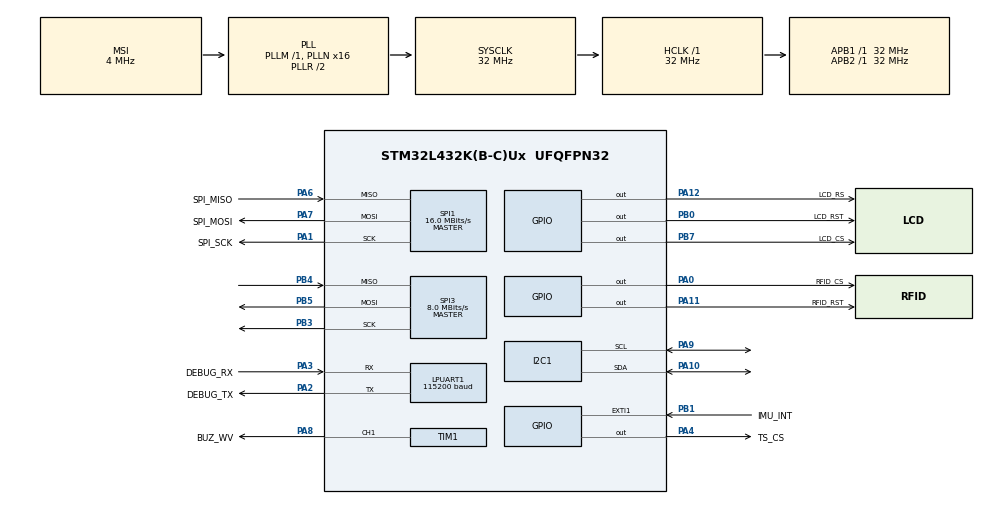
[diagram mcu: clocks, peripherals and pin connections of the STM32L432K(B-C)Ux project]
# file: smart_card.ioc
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Dma.Request0=SPI1_TX
Dma.Request1=SPI1_RX
Dma.SPI1_RX.1.Direction=DMA_PERIPH_TO_MEMORY
Dma.SPI1_RX.1.Instance=DMA1_Channel2
Dma.SPI1_RX.1.MemDataAlignment=DMA_MDATAALIGN_BYTE
Dma.SPI1_RX.1.MemInc=DMA_MINC_ENABLE
Dma.SPI1_RX.1.Mode=DMA_NORMAL
Dma.SPI1_RX.1.PeriphDataAlignment=DMA_PDATAALIGN_BYTE
Dma.SPI1_RX.1.PeriphInc=DMA_PINC_DISABLE
Dma.SPI1_RX.1.Priority=DMA_PRIORITY_LOW
Dma.SPI1_TX.0.Direction=DMA_MEMORY_TO_PERIPH
Dma.SPI1_TX.0.Instance=DMA1_Channel3
Dma.SPI1_TX.0.MemDataAlignment=DMA_MDATAALIGN_BYTE
Dma.SPI1_TX.0.MemInc=DMA_MINC_ENABLE
Dma.SPI1_TX.0.Mode=DMA_NORMAL
Dma.SPI1_TX.0.PeriphDataAlignment=DMA_PDATAALIGN_BYTE
Dma.SPI1_TX.0.PeriphInc=DMA_PINC_DISABLE
Dma.SPI1_TX.0.Priority=DMA_PRIORITY_LOW
I2C1.Timing=0x00B07CB4
LPUART1.BaudRate=115200
LPUART1.WordLength=UART_WORDLENGTH_8B
Mcu.Family=STM32L4
Mcu.Name=STM32L432K(B-C)Ux
Mcu.Package=UFQFPN32
NVIC.DMA1_Channel2_IRQn=true\:0\:0\:false\:false\:true\:false\:true\:true
NVIC.DMA1_Channel3_IRQn=true\:0\:0\:false\:false\:true\:false\:true\:true
NVIC.EXTI1_IRQn=true\:0\:0\:false\:false\:true\:true\:true\:true
NVIC.PriorityGroup=NVIC_PRIORITYGROUP_4
NVIC.TIM7_IRQn=true\:0\:0\:false\:false\:true\:true\:true\:true
PA0.GPIO_Label=RFID_CS
PA0.Signal=GPIO_Output
PA1.GPIO_Label=SPI_SCK
PA1.Mode=Full_Duplex_Master
PA1.Signal=SPI1_SCK
PA10.Mode=I2C
PA10.Signal=I2C1_SDA
PA11.GPIO_Label=RFID_RST
PA11.Signal=GPIO_Output
PA12.GPIO_Label=LCD_RS
PA12.GPIO_Speed=GPIO_SPEED_FREQ_VERY_HIGH
PA12.Signal=GPIO_Output
PA2.GPIO_Label=DEBUG_TX
PA2.Mode=Asynchronous
PA2.Signal=LPUART1_TX
PA3.GPIO_Label=DEBUG_RX
PA3.Mode=Asynchronous
PA3.Signal=LPUART1_RX
PA4.GPIO_Label=TS_CS
PA4.GPIO_Speed=GPIO_SPEED_FREQ_VERY_HIGH
PA4.PinState=GPIO_PIN_SET
PA4.Signal=GPIO_Output
PA6.GPIO_Label=SPI_MISO
PA6.Mode=Full_Duplex_Master
PA6.Signal=SPI1_MISO
PA7.GPIO_Label=SPI_MOSI
PA7.Mode=Full_Duplex_Master
PA7.Signal=SPI1_MOSI
PA8.GPIO_Label=BUZ_WV
PA8.Signal=S_TIM1_CH1
PA9.Mode=I2C
PA9.Signal=I2C1_SCL
PB0.GPIO_Label=LCD_RST
PB0.PinState=GPIO_PIN_SET
PB0.Signal=GPIO_Output
PB1.GPIO_Label=IMU_INT
PB1.GPIO_ModeDefaultEXTI=GPIO_MODE_IT_RISING_FALLING
PB1.Signal=GPXTI1
PB3\ (JTDO-TRACESWO).Mode=Full_Duplex_Master
PB3\ (JTDO-TRACESWO).Signal=SPI3_SCK
PB4\ (NJTRST).Mode=Full_Duplex_Master
PB4\ (NJTRST).Signal=SPI3_MISO
PB5.Mode=Full_Duplex_Master
PB5.Signal=SPI3_MOSI
PB7.GPIO_Label=LCD_CS
PB7.GPIO_Speed=GPIO_SPEED_FREQ_VERY_HIGH
PB7.PinState=GPIO_PIN_SET
PB7.Signal=GPIO_Output
ProjectManager.HeapSize=0x200
ProjectManager.StackSize=0x400
ProjectManager.TargetToolchain=STM32CubeIDE
RCC.AHBFreq_Value=32000000
RCC.APB1Freq_Value=32000000
RCC.APB1TimFreq_Value=32000000
RCC.APB2Freq_Value=32000000
RCC.APB2TimFreq_Value=32000000
RCC.CortexFreq_Value=32000000
RCC.HCLKFreq_Value=32000000
RCC.HSE_VALUE=8000000
RCC.HSI16_VALUE=16000000
RCC.HSI48_VALUE=48000000
RCC.HSI_VALUE=16000000
RCC.LSE_VALUE=32768
RCC.MSI_VALUE=4000000
RCC.PLLMUL=RCC_PLLMUL_4
RCC.PLLN=16
RCC.SYSCLKFreq_VALUE=32000000
RCC.SYSCLKSource=RCC_SYSCLKSOURCE_PLLCLK
RCC.VCOOutputFreq_Value=64000000
SH.S_TIM1_CH1.0=TIM1_CH1,PWM Generation1 CH1
SPI1.BaudRatePrescaler=SPI_BAUDRATEPRESCALER_2
SPI1.CalculateBaudRate=16.0 MBits/s
SPI1.DataSize=SPI_DATASIZE_8BIT
SPI1.Direction=SPI_DIRECTION_2LINES
SPI1.Mode=SPI_MODE_MASTER
SPI1.VirtualType=VM_MASTER
SPI3.BaudRatePrescaler=SPI_BAUDRATEPRESCALER_4
SPI3.CalculateBaudRate=8.0 MBits/s
SPI3.DataSize=SPI_DATASIZE_8BIT
SPI3.Direction=SPI_DIRECTION_2LINES
SPI3.Mode=SPI_MODE_MASTER
SPI3.VirtualType=VM_MASTER
TIM1.Channel-PWM\ Generation1\ CH1=TIM_CHANNEL_1
TIM1.Period=1000
TIM1.Pulse-PWM\ Generation1\ CH1=500
TIM7.Period=999
TIM7.Prescaler=31
VP_TIM1_VS_ClockSourceINT.Mode=Internal
VP_TIM7_VS_ClockSourceINT.Mode=Enable_Timer
board=NUCLEO-L432KC

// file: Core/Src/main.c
/* USER CODE BEGIN Header */
/**
 ******************************************************************************
 * @file           : main.c
 * @brief          : Main program body
 ******************************************************************************
 * @attention
 *
 * Copyright (c) 2024 STMicroelectronics.
 * All rights reserved.
 *
 * This software is licensed under terms that can be found in the LICENSE file
 * in the root directory of this software component.
 * If no LICENSE file comes with this software, it is provided AS-IS.
 *
 ******************************************************************************
 */
/* USER CODE END Header */
#include "main.h"

/* USER CODE BEGIN PD */
// TODO comment this out to test just card operations
// #define SCREEN
/* USER CODE END PD */

I2C_HandleTypeDef hi2c1;

UART_HandleTypeDef hlpuart1;

SPI_HandleTypeDef hspi1;
SPI_HandleTypeDef hspi3;
DMA_HandleTypeDef hdma_spi1_tx;
DMA_HandleTypeDef hdma_spi1_rx;

TIM_HandleTypeDef htim1;
TIM_HandleTypeDef htim7;

void SystemClock_Config(void);
static void MX_GPIO_Init(void);
static void MX_DMA_Init(void);
static void MX_LPUART1_UART_Init(void);
static void MX_SPI1_Init(void);
static void MX_SPI3_Init(void);
static void MX_I2C1_Init(void);
static void MX_TIM1_Init(void);
static void MX_TIM7_Init(void);
/* USER CODE BEGIN PFP */
void init();
void loop();
// struct contact_t get_data(uint8_t req);

/* USER CODE END PFP */

int main(void)
{

  /* MCU Configuration--------------------------------------------------------*/

  /* Reset of all peripherals, Initializes the Flash interface and the Systick. */
  HAL_Init();

  /* Configure the system clock */
  SystemClock_Config();

  /* Initialize all configured peripherals */
  MX_GPIO_Init();
  MX_DMA_Init();
  MX_LPUART1_UART_Init();
  MX_SPI1_Init();
  MX_SPI3_Init();
  MX_I2C1_Init();
  MX_TIM1_Init();
  MX_TIM7_Init();
  /* USER CODE BEGIN 2 */
    // HAL_Delay(5000);
    init();
    loop();
  /* USER CODE END 2 */

  /* Infinite loop */
  /* USER CODE BEGIN WHILE */
    while (1) {
        HAL_Delay(1000);
    /* USER CODE END WHILE */

    }
}

void SystemClock_Config(void)
{
  RCC_OscInitTypeDef RCC_OscInitStruct = {0};
  RCC_ClkInitTypeDef RCC_ClkInitStruct = {0};

  /** Configure the main internal regulator output voltage
  */
  if (HAL_PWREx_ControlVoltageScaling(PWR_REGULATOR_VOLTAGE_SCALE1) != HAL_OK)
  {
    Error_Handler();
  }

  /** Initializes the RCC Oscillators according to the specified parameters
  * in the RCC_OscInitTypeDef structure.
  */
  RCC_OscInitStruct.OscillatorType = RCC_OSCILLATORTYPE_MSI;
  RCC_OscInitStruct.MSIState = RCC_MSI_ON;
  RCC_OscInitStruct.MSICalibrationValue = 0;
  RCC_OscInitStruct.MSIClockRange = RCC_MSIRANGE_6;
  RCC_OscInitStruct.PLL.PLLState = RCC_PLL_ON;
  RCC_OscInitStruct.PLL.PLLSource = RCC_PLLSOURCE_MSI;
  RCC_OscInitStruct.PLL.PLLM = 1;
  RCC_OscInitStruct.PLL.PLLN = 16;
  RCC_OscInitStruct.PLL.PLLP = RCC_PLLP_DIV7;
  RCC_OscInitStruct.PLL.PLLQ = RCC_PLLQ_DIV2;
  RCC_OscInitStruct.PLL.PLLR = RCC_PLLR_DIV2;
  if (HAL_RCC_OscConfig(&RCC_OscInitStruct) != HAL_OK)
  {
    Error_Handler();
  }

  /** Initializes the CPU, AHB and APB buses clocks
  */
  RCC_ClkInitStruct.ClockType = RCC_CLOCKTYPE_HCLK|RCC_CLOCKTYPE_SYSCLK
                              |RCC_CLOCKTYPE_PCLK1|RCC_CLOCKTYPE_PCLK2;
  RCC_ClkInitStruct.SYSCLKSource = RCC_SYSCLKSOURCE_PLLCLK;
  RCC_ClkInitStruct.AHBCLKDivider = RCC_SYSCLK_DIV1;
  RCC_ClkInitStruct.APB1CLKDivider = RCC_HCLK_DIV1;
  RCC_ClkInitStruct.APB2CLKDivider = RCC_HCLK_DIV1;

  if (HAL_RCC_ClockConfig(&RCC_ClkInitStruct, FLASH_LATENCY_1) != HAL_OK)
  {
    Error_Handler();
  }
}

static void MX_I2C1_Init(void)
{

  hi2c1.Instance = I2C1;
  hi2c1.Init.Timing = 0x00B07CB4;
  hi2c1.Init.OwnAddress1 = 0;
  hi2c1.Init.AddressingMode = I2C_ADDRESSINGMODE_7BIT;
  hi2c1.Init.DualAddressMode = I2C_DUALADDRESS_DISABLE;
  hi2c1.Init.OwnAddress2 = 0;
  hi2c1.Init.OwnAddress2Masks = I2C_OA2_NOMASK;
  hi2c1.Init.GeneralCallMode = I2C_GENERALCALL_DISABLE;
  hi2c1.Init.NoStretchMode = I2C_NOSTRETCH_DISABLE;
  if (HAL_I2C_Init(&hi2c1) != HAL_OK)
  {
    Error_Handler();
  }

  /** Configure Analogue filter
  */
  if (HAL_I2CEx_ConfigAnalogFilter(&hi2c1, I2C_ANALOGFILTER_ENABLE) != HAL_OK)
  {
    Error_Handler();
  }

  /** Configure Digital filter
  */
  if (HAL_I2CEx_ConfigDigitalFilter(&hi2c1, 0) != HAL_OK)
  {
    Error_Handler();
  }

}

static void MX_LPUART1_UART_Init(void)
{

  hlpuart1.Instance = LPUART1;
  hlpuart1.Init.BaudRate = 115200;
  hlpuart1.Init.WordLength = UART_WORDLENGTH_8B;
  hlpuart1.Init.StopBits = UART_STOPBITS_1;
  hlpuart1.Init.Parity = UART_PARITY_NONE;
  hlpuart1.Init.Mode = UART_MODE_TX_RX;
  hlpuart1.Init.HwFlowCtl = UART_HWCONTROL_NONE;
  hlpuart1.Init.OneBitSampling = UART_ONE_BIT_SAMPLE_DISABLE;
  hlpuart1.AdvancedInit.AdvFeatureInit = UART_ADVFEATURE_NO_INIT;
  if (HAL_UART_Init(&hlpuart1) != HAL_OK)
  {
    Error_Handler();
  }

}

static void MX_SPI1_Init(void)
{

  /* SPI1 parameter configuration*/
  hspi1.Instance = SPI1;
  hspi1.Init.Mode = SPI_MODE_MASTER;
  hspi1.Init.Direction = SPI_DIRECTION_2LINES;
  hspi1.Init.DataSize = SPI_DATASIZE_8BIT;
  hspi1.Init.CLKPolarity = SPI_POLARITY_LOW;
  hspi1.Init.CLKPhase = SPI_PHASE_1EDGE;
  hspi1.Init.NSS = SPI_NSS_SOFT;
  hspi1.Init.BaudRatePrescaler = SPI_BAUDRATEPRESCALER_2;
  hspi1.Init.FirstBit = SPI_FIRSTBIT_MSB;
  hspi1.Init.TIMode = SPI_TIMODE_DISABLE;
  hspi1.Init.CRCCalculation = SPI_CRCCALCULATION_DISABLE;
  hspi1.Init.CRCPolynomial = 7;
  hspi1.Init.CRCLength = SPI_CRC_LENGTH_DATASIZE;
  hspi1.Init.NSSPMode = SPI_NSS_PULSE_ENABLE;
  if (HAL_SPI_Init(&hspi1) != HAL_OK)
  {
    Error_Handler();
  }

}

static void MX_SPI3_Init(void)
{

  /* SPI3 parameter configuration*/
  hspi3.Instance = SPI3;
  hspi3.Init.Mode = SPI_MODE_MASTER;
  hspi3.Init.Direction = SPI_DIRECTION_2LINES;
  hspi3.Init.DataSize = SPI_DATASIZE_8BIT;
  hspi3.Init.CLKPolarity = SPI_POLARITY_LOW;
  hspi3.Init.CLKPhase = SPI_PHASE_1EDGE;
  hspi3.Init.NSS = SPI_NSS_SOFT;
  hspi3.Init.BaudRatePrescaler = SPI_BAUDRATEPRESCALER_4;
  hspi3.Init.FirstBit = SPI_FIRSTBIT_MSB;
  hspi3.Init.TIMode = SPI_TIMODE_DISABLE;
  hspi3.Init.CRCCalculation = SPI_CRCCALCULATION_DISABLE;
  hspi3.Init.CRCPolynomial = 7;
  hspi3.Init.CRCLength = SPI_CRC_LENGTH_DATASIZE;
  hspi3.Init.NSSPMode = SPI_NSS_PULSE_ENABLE;
  if (HAL_SPI_Init(&hspi3) != HAL_OK)
  {
    Error_Handler();
  }

}

static void MX_TIM1_Init(void)
{

  TIM_ClockConfigTypeDef sClockSourceConfig = {0};
  TIM_MasterConfigTypeDef sMasterConfig = {0};
  TIM_OC_InitTypeDef sConfigOC = {0};
  TIM_BreakDeadTimeConfigTypeDef sBreakDeadTimeConfig = {0};

  htim1.Instance = TIM1;
  htim1.Init.Prescaler = 0;
  htim1.Init.CounterMode = TIM_COUNTERMODE_UP;
  htim1.Init.Period = 1000;
  htim1.Init.ClockDivision = TIM_CLOCKDIVISION_DIV1;
  htim1.Init.RepetitionCounter = 0;
  htim1.Init.AutoReloadPreload = TIM_AUTORELOAD_PRELOAD_DISABLE;
  if (HAL_TIM_Base_Init(&htim1) != HAL_OK)
  {
    Error_Handler();
  }
  sClockSourceConfig.ClockSource = TIM_CLOCKSOURCE_INTERNAL;
  if (HAL_TIM_ConfigClockSource(&htim1, &sClockSourceConfig) != HAL_OK)
  {
    Error_Handler();
  }
  if (HAL_TIM_PWM_Init(&htim1) != HAL_OK)
  {
    Error_Handler();
  }
  sMasterConfig.MasterOutputTrigger = TIM_TRGO_RESET;
  sMasterConfig.MasterOutputTrigger2 = TIM_TRGO2_RESET;
  sMasterConfig.MasterSlaveMode = TIM_MASTERSLAVEMODE_DISABLE;
  if (HAL_TIMEx_MasterConfigSynchronization(&htim1, &sMasterConfig) != HAL_OK)
  {
    Error_Handler();
  }
  sConfigOC.OCMode = TIM_OCMODE_PWM1;
  sConfigOC.Pulse = 500;
  sConfigOC.OCPolarity = TIM_OCPOLARITY_HIGH;
  sConfigOC.OCNPolarity = TIM_OCNPOLARITY_HIGH;
  sConfigOC.OCFastMode = TIM_OCFAST_DISABLE;
  sConfigOC.OCIdleState = TIM_OCIDLESTATE_RESET;
  sConfigOC.OCNIdleState = TIM_OCNIDLESTATE_RESET;
  if (HAL_TIM_PWM_ConfigChannel(&htim1, &sConfigOC, TIM_CHANNEL_1) != HAL_OK)
  {
    Error_Handler();
  }
  sBreakDeadTimeConfig.OffStateRunMode = TIM_OSSR_DISABLE;
  sBreakDeadTimeConfig.OffStateIDLEMode = TIM_OSSI_DISABLE;
  sBreakDeadTimeConfig.LockLevel = TIM_LOCKLEVEL_OFF;
  sBreakDeadTimeConfig.DeadTime = 0;
  sBreakDeadTimeConfig.BreakState = TIM_BREAK_DISABLE;
  sBreakDeadTimeConfig.BreakPolarity = TIM_BREAKPOLARITY_HIGH;
  sBreakDeadTimeConfig.BreakFilter = 0;
  sBreakDeadTimeConfig.Break2State = TIM_BREAK2_DISABLE;
  sBreakDeadTimeConfig.Break2Polarity = TIM_BREAK2POLARITY_HIGH;
  sBreakDeadTimeConfig.Break2Filter = 0;
  sBreakDeadTimeConfig.AutomaticOutput = TIM_AUTOMATICOUTPUT_DISABLE;
  if (HAL_TIMEx_ConfigBreakDeadTime(&htim1, &sBreakDeadTimeConfig) != HAL_OK)
  {
    Error_Handler();
  }
  HAL_TIM_MspPostInit(&htim1);

}

static void MX_TIM7_Init(void)
{

  TIM_MasterConfigTypeDef sMasterConfig = {0};

  htim7.Instance = TIM7;
  htim7.Init.Prescaler = 31;
  htim7.Init.CounterMode = TIM_COUNTERMODE_UP;
  htim7.Init.Period = 999;
  htim7.Init.AutoReloadPreload = TIM_AUTORELOAD_PRELOAD_DISABLE;
  if (HAL_TIM_Base_Init(&htim7) != HAL_OK)
  {
    Error_Handler();
  }
  sMasterConfig.MasterOutputTrigger = TIM_TRGO_RESET;
  sMasterConfig.MasterSlaveMode = TIM_MASTERSLAVEMODE_DISABLE;
  if (HAL_TIMEx_MasterConfigSynchronization(&htim7, &sMasterConfig) != HAL_OK)
  {
    Error_Handler();
  }

}

static void MX_DMA_Init(void)
{

  /* DMA controller clock enable */
  __HAL_RCC_DMA1_CLK_ENABLE();

  /* DMA interrupt init */
  /* DMA1_Channel2_IRQn interrupt configuration */
  HAL_NVIC_SetPriority(DMA1_Channel2_IRQn, 0, 0);
  HAL_NVIC_EnableIRQ(DMA1_Channel2_IRQn);
  /* DMA1_Channel3_IRQn interrupt configuration */
  HAL_NVIC_SetPriority(DMA1_Channel3_IRQn, 0, 0);
  HAL_NVIC_EnableIRQ(DMA1_Channel3_IRQn);

}

static void MX_GPIO_Init(void)
{
  GPIO_InitTypeDef GPIO_InitStruct = {0};

  /* GPIO Ports Clock Enable */
  __HAL_RCC_GPIOA_CLK_ENABLE();
  __HAL_RCC_GPIOB_CLK_ENABLE();

  /*Configure GPIO pin Output Level */
  HAL_GPIO_WritePin(GPIOA, RFID_CS_Pin|RFID_RST_Pin|LCD_RS_Pin, GPIO_PIN_RESET);

  /*Configure GPIO pin Output Level */
  HAL_GPIO_WritePin(TS_CS_GPIO_Port, TS_CS_Pin, GPIO_PIN_SET);

  /*Configure GPIO pin Output Level */
  HAL_GPIO_WritePin(GPIOB, LCD_RST_Pin|LCD_CS_Pin, GPIO_PIN_SET);

  /*Configure GPIO pins : RFID_CS_Pin RFID_RST_Pin */
  GPIO_InitStruct.Pin = RFID_CS_Pin|RFID_RST_Pin;
  GPIO_InitStruct.Mode = GPIO_MODE_OUTPUT_PP;
  GPIO_InitStruct.Pull = GPIO_NOPULL;
  GPIO_InitStruct.Speed = GPIO_SPEED_FREQ_LOW;
  HAL_GPIO_Init(GPIOA, &GPIO_InitStruct);

  /*Configure GPIO pins : TS_CS_Pin LCD_RS_Pin */
  GPIO_InitStruct.Pin = TS_CS_Pin|LCD_RS_Pin;
  GPIO_InitStruct.Mode = GPIO_MODE_OUTPUT_PP;
  GPIO_InitStruct.Pull = GPIO_NOPULL;
  GPIO_InitStruct.Speed = GPIO_SPEED_FREQ_VERY_HIGH;
  HAL_GPIO_Init(GPIOA, &GPIO_InitStruct);

  /*Configure GPIO pin : LCD_RST_Pin */
  GPIO_InitStruct.Pin = LCD_RST_Pin;
  GPIO_InitStruct.Mode = GPIO_MODE_OUTPUT_PP;
  GPIO_InitStruct.Pull = GPIO_NOPULL;
  GPIO_InitStruct.Speed = GPIO_SPEED_FREQ_LOW;
  HAL_GPIO_Init(LCD_RST_GPIO_Port, &GPIO_InitStruct);

  /*Configure GPIO pin : IMU_INT_Pin */
  GPIO_InitStruct.Pin = IMU_INT_Pin;
  GPIO_InitStruct.Mode = GPIO_MODE_IT_RISING_FALLING;
  GPIO_InitStruct.Pull = GPIO_NOPULL;
  HAL_GPIO_Init(IMU_INT_GPIO_Port, &GPIO_InitStruct);

  /*Configure GPIO pin : LCD_CS_Pin */
  GPIO_InitStruct.Pin = LCD_CS_Pin;
  GPIO_InitStruct.Mode = GPIO_MODE_OUTPUT_PP;
  GPIO_InitStruct.Pull = GPIO_NOPULL;
  GPIO_InitStruct.Speed = GPIO_SPEED_FREQ_VERY_HIGH;
  HAL_GPIO_Init(LCD_CS_GPIO_Port, &GPIO_InitStruct);

  /* EXTI interrupt init*/
  HAL_NVIC_SetPriority(EXTI1_IRQn, 0, 0);
  HAL_NVIC_EnableIRQ(EXTI1_IRQn);

}

/* USER CODE BEGIN 4 */

#ifdef __GNUC__
#define PUTCHAR_PROTOTYPE int __io_putchar(int ch)
#else
#define PUTCHAR_PROTOTYPE int fputc(int ch, FILE* f)
#endif /* __GNUC__ */
PUTCHAR_PROTOTYPE {
    HAL_UART_Transmit(&hlpuart1, (uint8_t*)&ch, 1, 0xFFFF);
    return ch;
}

/* USER CODE END 4 */

void Error_Handler(void)
{
    __disable_irq();
    while (1) {
    }
}
